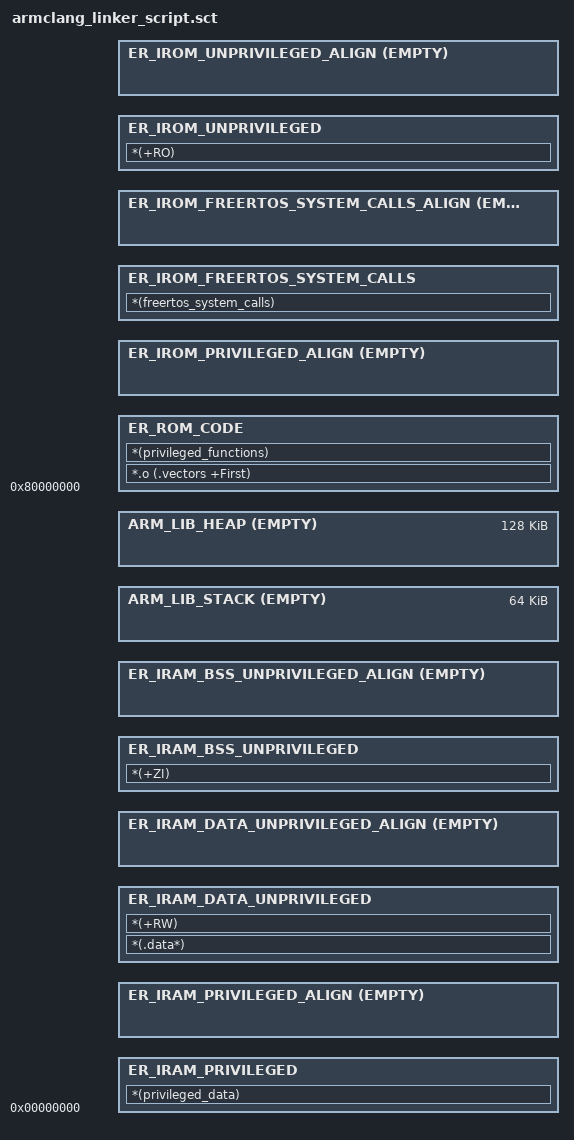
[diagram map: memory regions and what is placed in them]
#! armclang --target=aarch64-arm-none-eabi -march=armv8-r -E -x c
/*
 * Copyright (c) 2021-2025 Arm Limited. All rights reserved.
 *
 * Licensed under the Apache License, Version 2.0 (the "License");
 * you may not use this file except in compliance with the License.
 * You may obtain a copy of the License at
 *
 *     http://www.apache.org/licenses/LICENSE-2.0
 *
 * Unless required by applicable law or agreed to in writing, software
 * distributed under the License is distributed on an "AS IS" BASIS,
 * WITHOUT WARRANTIES OR CONDITIONS OF ANY KIND, either express or implied.
 * See the License for the specific language governing permissions and
 * limitations under the License.
 */

#define  __ROM_START           ( 0x80000000 )
#define  __RAM_START           ( 0x00000000 )
#define  __STACK_SIZE          ( 0x00010000 )
#define  __HEAP_SIZE           ( 0x00020000 )

;===============================================================================
;  LOAD REGION:  on-board flash 0x80000000 (4 MB)
;===============================================================================
LOAD_REGION  __ROM_START
{
    ;-- Code + RO data ---------------------------------------------------------
    ER_ROM_CODE __ROM_START ALIGN 64
    {
        *.o (.vectors +First)
        *(privileged_functions)
    }

    ER_IROM_PRIVILEGED_ALIGN +0 ALIGN 64 EMPTY 0x0
    {
    }

    ER_IROM_FREERTOS_SYSTEM_CALLS +0 ALIGN 64
    {
        *(freertos_system_calls)
    }

    ER_IROM_FREERTOS_SYSTEM_CALLS_ALIGN +0 ALIGN 64 EMPTY 0x0
    {
    }

    ER_IROM_UNPRIVILEGED +0 ALIGN 64
    {
        *(+RO)
    }

    ER_IROM_UNPRIVILEGED_ALIGN +0 ALIGN 64 EMPTY 0x0
    {
    }

    ER_IRAM_PRIVILEGED __RAM_START ALIGN 64
    {
        *(privileged_data)
    }

    ER_IRAM_PRIVILEGED_ALIGN +0 ALIGN 64 EMPTY 0x0
    {
    }

    ER_IRAM_DATA_UNPRIVILEGED +0 ALIGN 64
    {
        *(.data*)
        *(+RW)
    }

    ER_IRAM_DATA_UNPRIVILEGED_ALIGN +0 ALIGN 64 EMPTY 0x0
    {
    }

    ER_IRAM_BSS_UNPRIVILEGED +0 ALIGN 64
    {
        *(+ZI)
    }

    ER_IRAM_BSS_UNPRIVILEGED_ALIGN +0 ALIGN 64 EMPTY 0x0
    {
    }

    ;-- Stack ------------------------------------------------------------------
    ARM_LIB_STACK +0 ALIGN 16 EMPTY (__STACK_SIZE) {
    }

    ;-- Heap -------------------------------------------------------------------
    ARM_LIB_HEAP +0 ALIGN 16 EMPTY (__HEAP_SIZE) {
    }
}
